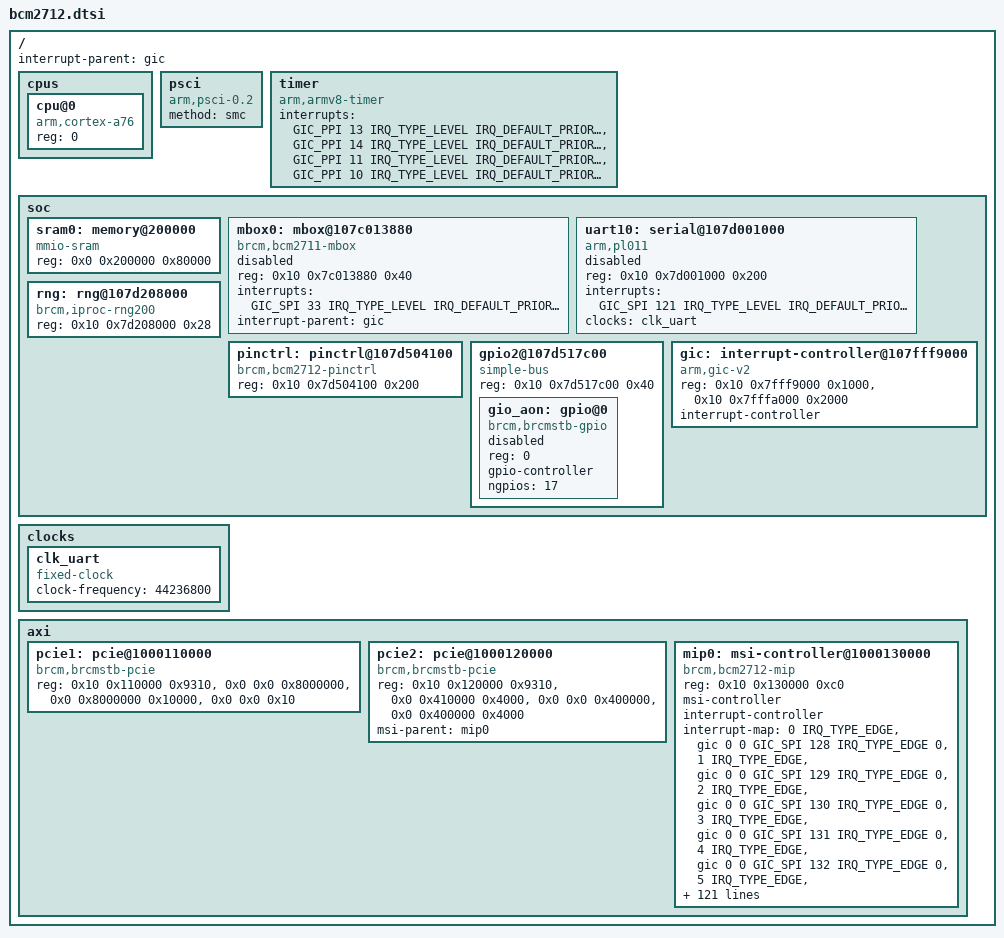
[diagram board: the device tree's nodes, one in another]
/*
 * Copyright 2024 Myeonghyeon Park <myeonghyeon@tsnlab.com>
 *
 * SPDX-License-Identifier: Apache-2.0
 */

#include <arm64/armv8-a.dtsi>
#include <zephyr/dt-bindings/interrupt-controller/arm-gic.h>

/ {
	interrupt-parent = <&gic>;

	cpus {
		#address-cells = <1>;
		#size-cells = <0>;

		cpu@0 {
			compatible = "arm,cortex-a76";
			reg = <0>;
			device_type = "cpu";
		};
	};

	psci {
		compatible = "arm,psci-0.2";
		method = "smc";
	};

	timer {
		compatible = "arm,armv8-timer";
		interrupts = <GIC_PPI 13 IRQ_TYPE_LEVEL
			      IRQ_DEFAULT_PRIORITY>,
			     <GIC_PPI 14 IRQ_TYPE_LEVEL
			      IRQ_DEFAULT_PRIORITY>,
			     <GIC_PPI 11 IRQ_TYPE_LEVEL
			      IRQ_DEFAULT_PRIORITY>,
			     <GIC_PPI 10 IRQ_TYPE_LEVEL
			      IRQ_DEFAULT_PRIORITY>;
	};

	soc {
		#address-cells = <2>;
		#size-cells = <1>;

		sram0: memory@200000 {
			compatible = "mmio-sram";
			reg = <0x0 0x200000 0x80000>;
			device_type = "memory";
		};

		mbox0: mbox@107c013880 {
			compatible = "brcm,bcm2711-mbox";
			reg = <0x10 0x7c013880 0x40>;
			interrupts = <GIC_SPI 33 IRQ_TYPE_LEVEL
				      IRQ_DEFAULT_PRIORITY>;
			interrupt-parent = <&gic>;
			#mbox-cells = <1>;
			status = "disabled";
		};

		uart10: serial@107d001000 {
			compatible = "arm,pl011";
			reg = <0x10 0x7d001000 0x200>;
			interrupts = <GIC_SPI 121 IRQ_TYPE_LEVEL
				      IRQ_DEFAULT_PRIORITY>;
			interrupt-names = "irq_121";
			clocks = <&clk_uart>;
			status = "disabled";
		};

		rng: rng@107d208000 {
			compatible = "brcm,iproc-rng200";
			reg = <0x10 0x7d208000 0x28>;
			status = "okay";
		};

		pinctrl: pinctrl@107d504100 {
			compatible = "brcm,bcm2712-pinctrl";
			reg = <0x10 0x7d504100 0x200>;
			status = "okay";
		};

		gpio2@107d517c00 {
			compatible = "simple-bus";
			reg = <0x10 0x7d517c00 0x40>;

			#address-cells = <1>;
			#size-cells = <0>;

			gio_aon: gpio@0 {
				compatible = "brcm,brcmstb-gpio";
				reg = <0>;
				gpio-controller;
				#gpio-cells = <2>;
				ngpios = <17>;
				status = "disabled";
			};
		};

		gic: interrupt-controller@107fff9000 {
			compatible = "arm,gic-v2", "arm,gic";
			reg = <0x10 0x7fff9000 0x1000>,
			      <0x10 0x7fffa000 0x2000>;
			interrupt-controller;
			#interrupt-cells = <4>;
			#address-cells = <2>;
			status = "okay";
		};
	};

	clocks {
		clk_uart: clk_uart {
			compatible = "fixed-clock";
			clock-frequency = <44236800>;
			#clock-cells = <0>;
		};
	};

	axi {
		#address-cells = <2>;
		#size-cells = <1>;

		pcie1: pcie@1000110000 {
			compatible = "brcm,brcmstb-pcie";
			reg = <0x10 0x110000 0x9310>,
			      <0x0 0x0 0x8000000>,
			      <0x0 0x8000000 0x10000>,
			      <0x0 0x0 0x10>;
			ranges = <0x02000000 0x0 0x0 0x1b 0x0 0x00 0xfffffffc>,
				 <0x43000000 0x4 0x0 0x18 0x0 0x03 0x00000000>,
				 <0x03000000 0x0 0x0 0x10 0x0 0x10 0x00000000>;
			#address-cells = <3>;
			#size-cells = <2>;
			status = "okay";
		};

		pcie2: pcie@1000120000 {
			compatible = "brcm,brcmstb-pcie";
			reg = <0x10 0x120000 0x9310>,
			      <0x0 0x410000 0x4000>,
			      <0x0 0x0 0x400000>,
			      <0x0 0x400000 0x4000>;
			ranges = <0x02000000 0x0 0x0 0x1f 0x0 0x00 0xfffffffc>,
				 <0x43000000 0x4 0x0 0x1c 0x0 0x03 0x00000000>,
				 <0x02000000 0x0 0x0 0x1f 0x0 0x00 0x00400000>;
			#address-cells = <3>;
			#size-cells = <2>;
			msi-parent = <&mip0>;
			status = "okay";
		};

		mip0: msi-controller@1000130000 {
			compatible = "brcm,bcm2712-mip";
			reg = <0x10 0x130000 0xc0>;
			msi-controller;
			interrupt-controller;
			#interrupt-cells = <2>;
			#address-cells = <0>;
			interrupt-map = <0 IRQ_TYPE_EDGE &gic 0 0 GIC_SPI 128 IRQ_TYPE_EDGE 0>,
					<1 IRQ_TYPE_EDGE &gic 0 0 GIC_SPI 129 IRQ_TYPE_EDGE 0>,
					<2 IRQ_TYPE_EDGE &gic 0 0 GIC_SPI 130 IRQ_TYPE_EDGE 0>,
					<3 IRQ_TYPE_EDGE &gic 0 0 GIC_SPI 131 IRQ_TYPE_EDGE 0>,
					<4 IRQ_TYPE_EDGE &gic 0 0 GIC_SPI 132 IRQ_TYPE_EDGE 0>,
					<5 IRQ_TYPE_EDGE &gic 0 0 GIC_SPI 133 IRQ_TYPE_EDGE 0>,
					<6 IRQ_TYPE_EDGE &gic 0 0 GIC_SPI 134 IRQ_TYPE_EDGE 0>,
					<7 IRQ_TYPE_EDGE &gic 0 0 GIC_SPI 135 IRQ_TYPE_EDGE 0>,
					<8 IRQ_TYPE_EDGE &gic 0 0 GIC_SPI 136 IRQ_TYPE_EDGE 0>,
					<9 IRQ_TYPE_EDGE &gic 0 0 GIC_SPI 137 IRQ_TYPE_EDGE 0>,
					<10 IRQ_TYPE_EDGE &gic 0 0 GIC_SPI 138 IRQ_TYPE_EDGE 0>,
					<11 IRQ_TYPE_EDGE &gic 0 0 GIC_SPI 139 IRQ_TYPE_EDGE 0>,
					<12 IRQ_TYPE_EDGE &gic 0 0 GIC_SPI 140 IRQ_TYPE_EDGE 0>,
					<13 IRQ_TYPE_EDGE &gic 0 0 GIC_SPI 141 IRQ_TYPE_EDGE 0>,
					<14 IRQ_TYPE_EDGE &gic 0 0 GIC_SPI 142 IRQ_TYPE_EDGE 0>,
					<15 IRQ_TYPE_EDGE &gic 0 0 GIC_SPI 143 IRQ_TYPE_EDGE 0>,
					<16 IRQ_TYPE_EDGE &gic 0 0 GIC_SPI 144 IRQ_TYPE_EDGE 0>,
					<17 IRQ_TYPE_EDGE &gic 0 0 GIC_SPI 145 IRQ_TYPE_EDGE 0>,
					<18 IRQ_TYPE_EDGE &gic 0 0 GIC_SPI 146 IRQ_TYPE_EDGE 0>,
					<19 IRQ_TYPE_EDGE &gic 0 0 GIC_SPI 147 IRQ_TYPE_EDGE 0>,
					<20 IRQ_TYPE_EDGE &gic 0 0 GIC_SPI 148 IRQ_TYPE_EDGE 0>,
					<21 IRQ_TYPE_EDGE &gic 0 0 GIC_SPI 149 IRQ_TYPE_EDGE 0>,
					<22 IRQ_TYPE_EDGE &gic 0 0 GIC_SPI 150 IRQ_TYPE_EDGE 0>,
					<23 IRQ_TYPE_EDGE &gic 0 0 GIC_SPI 151 IRQ_TYPE_EDGE 0>,
					<24 IRQ_TYPE_EDGE &gic 0 0 GIC_SPI 152 IRQ_TYPE_EDGE 0>,
					<25 IRQ_TYPE_EDGE &gic 0 0 GIC_SPI 153 IRQ_TYPE_EDGE 0>,
					<26 IRQ_TYPE_EDGE &gic 0 0 GIC_SPI 154 IRQ_TYPE_EDGE 0>,
					<27 IRQ_TYPE_EDGE &gic 0 0 GIC_SPI 155 IRQ_TYPE_EDGE 0>,
					<28 IRQ_TYPE_EDGE &gic 0 0 GIC_SPI 156 IRQ_TYPE_EDGE 0>,
					<29 IRQ_TYPE_EDGE &gic 0 0 GIC_SPI 157 IRQ_TYPE_EDGE 0>,
					<30 IRQ_TYPE_EDGE &gic 0 0 GIC_SPI 158 IRQ_TYPE_EDGE 0>,
					<31 IRQ_TYPE_EDGE &gic 0 0 GIC_SPI 159 IRQ_TYPE_EDGE 0>,
					<32 IRQ_TYPE_EDGE &gic 0 0 GIC_SPI 160 IRQ_TYPE_EDGE 0>,
					<33 IRQ_TYPE_EDGE &gic 0 0 GIC_SPI 161 IRQ_TYPE_EDGE 0>,
					<34 IRQ_TYPE_EDGE &gic 0 0 GIC_SPI 162 IRQ_TYPE_EDGE 0>,
					<35 IRQ_TYPE_EDGE &gic 0 0 GIC_SPI 163 IRQ_TYPE_EDGE 0>,
					<36 IRQ_TYPE_EDGE &gic 0 0 GIC_SPI 164 IRQ_TYPE_EDGE 0>,
					<37 IRQ_TYPE_EDGE &gic 0 0 GIC_SPI 165 IRQ_TYPE_EDGE 0>,
					<38 IRQ_TYPE_EDGE &gic 0 0 GIC_SPI 166 IRQ_TYPE_EDGE 0>,
					<39 IRQ_TYPE_EDGE &gic 0 0 GIC_SPI 167 IRQ_TYPE_EDGE 0>,
					<40 IRQ_TYPE_EDGE &gic 0 0 GIC_SPI 168 IRQ_TYPE_EDGE 0>,
					<41 IRQ_TYPE_EDGE &gic 0 0 GIC_SPI 169 IRQ_TYPE_EDGE 0>,
					<42 IRQ_TYPE_EDGE &gic 0 0 GIC_SPI 170 IRQ_TYPE_EDGE 0>,
					<43 IRQ_TYPE_EDGE &gic 0 0 GIC_SPI 171 IRQ_TYPE_EDGE 0>,
					<44 IRQ_TYPE_EDGE &gic 0 0 GIC_SPI 172 IRQ_TYPE_EDGE 0>,
					<45 IRQ_TYPE_EDGE &gic 0 0 GIC_SPI 173 IRQ_TYPE_EDGE 0>,
					<46 IRQ_TYPE_EDGE &gic 0 0 GIC_SPI 174 IRQ_TYPE_EDGE 0>,
					<47 IRQ_TYPE_EDGE &gic 0 0 GIC_SPI 175 IRQ_TYPE_EDGE 0>,
					<48 IRQ_TYPE_EDGE &gic 0 0 GIC_SPI 176 IRQ_TYPE_EDGE 0>,
					<49 IRQ_TYPE_EDGE &gic 0 0 GIC_SPI 177 IRQ_TYPE_EDGE 0>,
					<50 IRQ_TYPE_EDGE &gic 0 0 GIC_SPI 178 IRQ_TYPE_EDGE 0>,
					<51 IRQ_TYPE_EDGE &gic 0 0 GIC_SPI 179 IRQ_TYPE_EDGE 0>,
					<52 IRQ_TYPE_EDGE &gic 0 0 GIC_SPI 180 IRQ_TYPE_EDGE 0>,
					<53 IRQ_TYPE_EDGE &gic 0 0 GIC_SPI 181 IRQ_TYPE_EDGE 0>,
					<54 IRQ_TYPE_EDGE &gic 0 0 GIC_SPI 182 IRQ_TYPE_EDGE 0>,
					<55 IRQ_TYPE_EDGE &gic 0 0 GIC_SPI 183 IRQ_TYPE_EDGE 0>,
					<56 IRQ_TYPE_EDGE &gic 0 0 GIC_SPI 184 IRQ_TYPE_EDGE 0>,
					<57 IRQ_TYPE_EDGE &gic 0 0 GIC_SPI 185 IRQ_TYPE_EDGE 0>,
					<58 IRQ_TYPE_EDGE &gic 0 0 GIC_SPI 186 IRQ_TYPE_EDGE 0>,
					<59 IRQ_TYPE_EDGE &gic 0 0 GIC_SPI 187 IRQ_TYPE_EDGE 0>,
					<60 IRQ_TYPE_EDGE &gic 0 0 GIC_SPI 188 IRQ_TYPE_EDGE 0>,
					<61 IRQ_TYPE_EDGE &gic 0 0 GIC_SPI 189 IRQ_TYPE_EDGE 0>,
					<62 IRQ_TYPE_EDGE &gic 0 0 GIC_SPI 190 IRQ_TYPE_EDGE 0>,
					<63 IRQ_TYPE_EDGE &gic 0 0 GIC_SPI 191 IRQ_TYPE_EDGE 0>;
			brcm,msi-base-spi = <128>;
			brcm,msi-num-spis = <64>;
			brcm,msi-offset = <0>;
			brcm,msi-pci-addr = <0xff 0xfffff000>;
		};
	};
};
